# CLKMON register map
Registers from a debugger description file.
Registers are 32-bit, write-only, no defined reset value unless marked. A register's access mark holds for its fields unless they carry their own. Addresses are absolute; registers are grouped by the start of their names; lines under a group give offsets from that group; [hi:lo] are bit positions; {n}, {i} and the like mark numbered series; 'fields as' and 'values as' point back to an identical list; <NAME> marks a mode.

## CLKMON
0x51005000 CLKMON/SetEnable
  [31:0] SetEnable
0x51005004 CLKMON/ClearEnable
  [31:0] ClearEnable
0x51005008 CLKMON/SetEnableResetSoft
  [31:0] SetEnableResetSoft
0x5100500C CLKMON/ClearEnableResetSoft
  [31:0] ClearEnableResetSoft
0x51005010 CLKMON/SetEnable100Khz
  [31:0] SetEnable100Khz
0x51005014 CLKMON/ClearEnable100Khz
  [31:0] ClearEnable100Khz
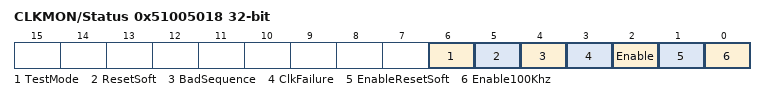
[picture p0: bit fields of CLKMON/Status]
0x51005018 CLKMON/Status ro
  [6] TestMode, [5] ResetSoft, [4] BadSequence, [3] ClkFailure, [2] Enable, [1] EnableResetSoft, [0] Enable100Khz
0x5100501C CLKMON/SetTestMode
  [31:0] SetTestMode
0x51005020 CLKMON/ClearTestMode
  [31:0] ClearTestMode
0x51005024 CLKMON/ClearStatusWindow
  [31:0] ClearStatusWindow
0x51005028 CLKMON/StatusWindow access not given
  [0] StatusWindow
